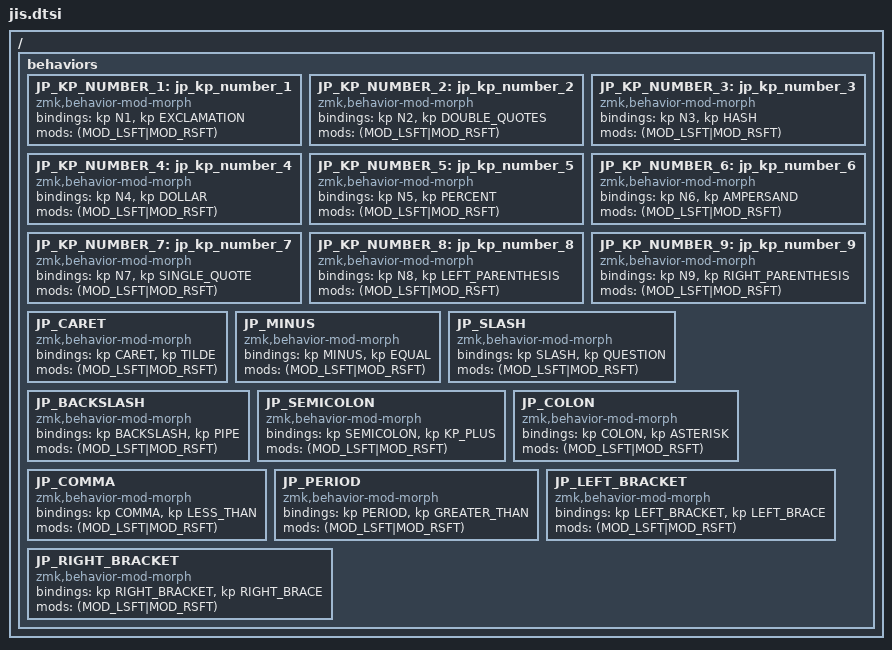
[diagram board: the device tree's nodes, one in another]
/ {
    behaviors {
        JP_KP_NUMBER_1: jp_kp_number_1 {
            compatible = "zmk,behavior-mod-morph";
            #binding-cells = <0>;
            bindings = <&kp N1>, <&kp EXCLAMATION>;   // 1 → !
            mods = <(MOD_LSFT|MOD_RSFT)>;
        };

        JP_KP_NUMBER_2: jp_kp_number_2 {
            compatible = "zmk,behavior-mod-morph";
            #binding-cells = <0>;
            bindings = <&kp N2>, <&kp DOUBLE_QUOTES>;     // 2 → "
            mods = <(MOD_LSFT|MOD_RSFT)>;
        };

        JP_KP_NUMBER_3: jp_kp_number_3 {
            compatible = "zmk,behavior-mod-morph";
            #binding-cells = <0>;
            bindings = <&kp N3>, <&kp HASH>;   // 3 → #
            mods = <(MOD_LSFT|MOD_RSFT)>;
        };

        JP_KP_NUMBER_4: jp_kp_number_4 {
            compatible = "zmk,behavior-mod-morph";
            #binding-cells = <0>;
            bindings = <&kp N4>, <&kp DOLLAR>; // 4 → $
            mods = <(MOD_LSFT|MOD_RSFT)>;
        };

        JP_KP_NUMBER_5: jp_kp_number_5 {
            compatible = "zmk,behavior-mod-morph";
            #binding-cells = <0>;
            bindings = <&kp N5>, <&kp PERCENT>; // 5 → %
            mods = <(MOD_LSFT|MOD_RSFT)>;
        };

        JP_KP_NUMBER_6: jp_kp_number_6 {
            compatible = "zmk,behavior-mod-morph";
            #binding-cells = <0>;
            bindings = <&kp N6>, <&kp AMPERSAND>;  // 6 → &
            mods = <(MOD_LSFT|MOD_RSFT)>;
        };

        JP_KP_NUMBER_7: jp_kp_number_7 {
            compatible = "zmk,behavior-mod-morph";
            #binding-cells = <0>;
            bindings = <&kp N7>, <&kp SINGLE_QUOTE>; // 7 → '
            mods = <(MOD_LSFT|MOD_RSFT)>;
        };

        JP_KP_NUMBER_8: jp_kp_number_8 {
            compatible = "zmk,behavior-mod-morph";
            #binding-cells = <0>;
            bindings = <&kp N8>, <&kp LEFT_PARENTHESIS>; // 8 → (
            mods = <(MOD_LSFT|MOD_RSFT)>;
        };

        JP_KP_NUMBER_9: jp_kp_number_9 {
            compatible = "zmk,behavior-mod-morph";
            #binding-cells = <0>;
            bindings = <&kp N9>, <&kp RIGHT_PARENTHESIS>; // 9 → )
            mods = <(MOD_LSFT|MOD_RSFT)>;
        };

        JP_CARET: JP_CARET {
            compatible = "zmk,behavior-mod-morph";
            #binding-cells = <0>;
            bindings = <&kp CARET>, <&kp TILDE>; // ^ → ~
            mods = <(MOD_LSFT|MOD_RSFT)>;
        };

        JP_MINUS: JP_MINUS {
            compatible = "zmk,behavior-mod-morph";
            #binding-cells = <0>;
            bindings = <&kp MINUS>, <&kp EQUAL>; // - → =
            mods = <(MOD_LSFT|MOD_RSFT)>;
        };

        JP_SLASH: JP_SLASH {
            compatible = "zmk,behavior-mod-morph";
            #binding-cells = <0>;
            bindings = <&kp SLASH>, <&kp QUESTION>; // / → ?
            mods = <(MOD_LSFT|MOD_RSFT)>;
        };

        JP_BACKSLASH: JP_BACKSLASH {
            compatible = "zmk,behavior-mod-morph";
            #binding-cells = <0>;
            bindings = <&kp BACKSLASH>, <&kp PIPE>; // \ → |
            mods = <(MOD_LSFT|MOD_RSFT)>;
        };

        JP_SEMICOLON: JP_SEMICOLON {
            compatible = "zmk,behavior-mod-morph";
            #binding-cells = <0>;
            bindings = <&kp SEMICOLON>, <&kp KP_PLUS>; // ; → +
            mods = <(MOD_LSFT|MOD_RSFT)>;
        };

        JP_COLON: JP_COLON {
            compatible = "zmk,behavior-mod-morph";
            #binding-cells = <0>;
            bindings = <&kp COLON>, <&kp ASTERISK>; // : → *
            mods = <(MOD_LSFT|MOD_RSFT)>;
        };

        JP_COMMA: JP_COMMA {
            compatible = "zmk,behavior-mod-morph";
            #binding-cells = <0>;
            bindings = <&kp COMMA>, <&kp LESS_THAN>; // , → <
            mods = <(MOD_LSFT|MOD_RSFT)>;
        };

        JP_PERIOD: JP_PERIOD {
            compatible = "zmk,behavior-mod-morph";
            #binding-cells = <0>;
            bindings = <&kp PERIOD>, <&kp GREATER_THAN>; // . → >
            mods = <(MOD_LSFT|MOD_RSFT)>;
        };

        JP_LEFT_BRACKET: JP_LEFT_BRACKET {
            compatible = "zmk,behavior-mod-morph";
            #binding-cells = <0>;
            bindings = <&kp LEFT_BRACKET>, <&kp LEFT_BRACE>; // [ → {
            mods = <(MOD_LSFT|MOD_RSFT)>;
        };

        JP_RIGHT_BRACKET: JP_RIGHT_BRACKET {
            compatible = "zmk,behavior-mod-morph";
            #binding-cells = <0>;
            bindings = <&kp RIGHT_BRACKET>, <&kp RIGHT_BRACE>; // ] → }
            mods = <(MOD_LSFT|MOD_RSFT)>;
        };
    };
};
